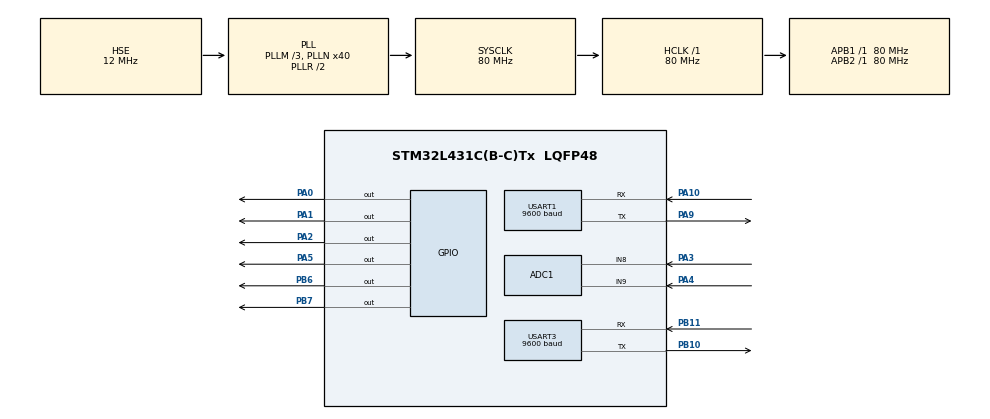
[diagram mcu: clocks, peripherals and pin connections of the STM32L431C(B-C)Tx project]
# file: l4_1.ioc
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ADC1.Channel-0\#ChannelRegularConversion=ADC_CHANNEL_8
ADC1.Channel-1\#ChannelRegularConversion=ADC_CHANNEL_9
ADC1.ContinuousConvMode=ENABLE
ADC1.DMAContinuousRequests=ENABLE
ADC1.NbrOfConversion=2
ADC1.NbrOfConversionFlag=1
ADC1.OffsetNumber-0\#ChannelRegularConversion=ADC_OFFSET_NONE
ADC1.OffsetNumber-1\#ChannelRegularConversion=ADC_OFFSET_NONE
ADC1.Rank-0\#ChannelRegularConversion=1
ADC1.Rank-1\#ChannelRegularConversion=2
ADC1.SamplingTime-0\#ChannelRegularConversion=ADC_SAMPLETIME_24CYCLES_5
ADC1.SamplingTime-1\#ChannelRegularConversion=ADC_SAMPLETIME_24CYCLES_5
ADC1.master=1
Dma.ADC1.2.Direction=DMA_PERIPH_TO_MEMORY
Dma.ADC1.2.Instance=DMA1_Channel1
Dma.ADC1.2.MemDataAlignment=DMA_MDATAALIGN_HALFWORD
Dma.ADC1.2.MemInc=DMA_MINC_ENABLE
Dma.ADC1.2.Mode=DMA_CIRCULAR
Dma.ADC1.2.PeriphDataAlignment=DMA_PDATAALIGN_HALFWORD
Dma.ADC1.2.PeriphInc=DMA_PINC_DISABLE
Dma.ADC1.2.Priority=DMA_PRIORITY_LOW
Dma.Request0=USART1_RX
Dma.Request1=USART3_RX
Dma.Request2=ADC1
Dma.Request3=USART1_TX
Dma.USART1_RX.0.Direction=DMA_PERIPH_TO_MEMORY
Dma.USART1_RX.0.Instance=DMA1_Channel5
Dma.USART1_RX.0.MemDataAlignment=DMA_MDATAALIGN_BYTE
Dma.USART1_RX.0.MemInc=DMA_MINC_ENABLE
Dma.USART1_RX.0.Mode=DMA_NORMAL
Dma.USART1_RX.0.PeriphDataAlignment=DMA_PDATAALIGN_BYTE
Dma.USART1_RX.0.PeriphInc=DMA_PINC_DISABLE
Dma.USART1_RX.0.Priority=DMA_PRIORITY_LOW
Dma.USART1_TX.3.Direction=DMA_MEMORY_TO_PERIPH
Dma.USART1_TX.3.Instance=DMA1_Channel4
Dma.USART1_TX.3.MemDataAlignment=DMA_MDATAALIGN_BYTE
Dma.USART1_TX.3.MemInc=DMA_MINC_ENABLE
Dma.USART1_TX.3.Mode=DMA_NORMAL
Dma.USART1_TX.3.PeriphDataAlignment=DMA_PDATAALIGN_BYTE
Dma.USART1_TX.3.PeriphInc=DMA_PINC_DISABLE
Dma.USART1_TX.3.Priority=DMA_PRIORITY_LOW
Dma.USART3_RX.1.Direction=DMA_PERIPH_TO_MEMORY
Dma.USART3_RX.1.Instance=DMA1_Channel3
Dma.USART3_RX.1.MemDataAlignment=DMA_MDATAALIGN_BYTE
Dma.USART3_RX.1.MemInc=DMA_MINC_ENABLE
Dma.USART3_RX.1.Mode=DMA_NORMAL
Dma.USART3_RX.1.PeriphDataAlignment=DMA_PDATAALIGN_BYTE
Dma.USART3_RX.1.PeriphInc=DMA_PINC_DISABLE
Dma.USART3_RX.1.Priority=DMA_PRIORITY_LOW
Mcu.Family=STM32L4
Mcu.Name=STM32L431C(B-C)Tx
Mcu.Package=LQFP48
NVIC.ADC1_IRQn=true\:0\:0\:false\:false\:true\:true\:true\:true
NVIC.DMA1_Channel1_IRQn=true\:0\:0\:false\:false\:true\:false\:true\:true
NVIC.DMA1_Channel3_IRQn=true\:0\:0\:false\:false\:true\:false\:true\:true
NVIC.DMA1_Channel4_IRQn=true\:0\:0\:false\:false\:true\:false\:true\:true
NVIC.DMA1_Channel5_IRQn=true\:0\:0\:false\:false\:true\:false\:true\:true
NVIC.PriorityGroup=NVIC_PRIORITYGROUP_4
NVIC.TIM2_IRQn=true\:0\:0\:false\:false\:true\:true\:true\:true
NVIC.USART1_IRQn=true\:0\:0\:false\:false\:true\:true\:true\:true
NVIC.USART3_IRQn=true\:0\:0\:false\:false\:true\:true\:true\:true
PA0.PinState=GPIO_PIN_SET
PA0.Signal=GPIO_Output
PA1.PinState=GPIO_PIN_SET
PA1.Signal=GPIO_Output
PA10.Mode=Asynchronous
PA10.Signal=USART1_RX
PA13\ (JTMS-SWDIO).Mode=Serial_Wire
PA13\ (JTMS-SWDIO).Signal=SYS_JTMS-SWDIO
PA14\ (JTCK-SWCLK).Mode=Serial_Wire
PA14\ (JTCK-SWCLK).Signal=SYS_JTCK-SWCLK
PA2.PinState=GPIO_PIN_SET
PA2.Signal=GPIO_Output
PA3.Signal=ADCx_IN8
PA4.Signal=ADCx_IN9
PA5.Signal=GPIO_Output
PA9.Mode=Asynchronous
PA9.Signal=USART1_TX
PB10.Mode=Asynchronous
PB10.Signal=USART3_TX
PB11.Mode=Asynchronous
PB11.Signal=USART3_RX
PB6.Signal=GPIO_Output
PB7.Signal=GPIO_Output
PH0-OSC_IN\ (PH0).Mode=HSE-External-Oscillator
PH0-OSC_IN\ (PH0).Signal=RCC_OSC_IN
PH1-OSC_OUT\ (PH1).Mode=HSE-External-Oscillator
PH1-OSC_OUT\ (PH1).Signal=RCC_OSC_OUT
ProjectManager.HeapSize=0x200
ProjectManager.StackSize=0x400
ProjectManager.TargetToolchain=MDK-ARM V5.32
RCC.ADCFreq_Value=32000000
RCC.AHBFreq_Value=80000000
RCC.APB1Freq_Value=80000000
RCC.APB1TimFreq_Value=80000000
RCC.APB2Freq_Value=80000000
RCC.APB2TimFreq_Value=80000000
RCC.CortexFreq_Value=80000000
RCC.HCLKFreq_Value=80000000
RCC.HSE_VALUE=12000000
RCC.HSI48_VALUE=48000000
RCC.HSI_VALUE=16000000
RCC.LSE_VALUE=32768
RCC.MSI_VALUE=4000000
RCC.PLLM=3
RCC.PLLN=40
RCC.PLLSAI1N=16
RCC.PLLSourceVirtual=RCC_PLLSOURCE_HSE
RCC.SYSCLKFreq_VALUE=80000000
RCC.SYSCLKSource=RCC_SYSCLKSOURCE_PLLCLK
RCC.VCOOutputFreq_Value=160000000
SH.ADCx_IN8.0=ADC1_IN8,IN8-Single-Ended
SH.ADCx_IN9.0=ADC1_IN9,IN9-Single-Ended
TIM2.Period=800 - 1
TIM2.Prescaler=79 - 1
TIM6.Prescaler=80 - 1
USART1.BaudRate=9600
USART1.Parity=PARITY_EVEN
USART1.VirtualMode-Asynchronous=VM_ASYNC
USART1.WordLength=WORDLENGTH_9B
USART3.BaudRate=9600
USART3.VirtualMode-Asynchronous=VM_ASYNC
USART3.WordLength=WORDLENGTH_8B
VP_TIM2_VS_ClockSourceINT.Mode=Internal
VP_TIM6_VS_ClockSourceINT.Mode=Enable_Timer
board=custom

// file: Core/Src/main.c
/* USER CODE BEGIN Header */
/**
  ******************************************************************************
  * @file           : main.c
  * @brief          : Main program body
  ******************************************************************************
  * @attention
  *
  * Copyright (c) 2026 STMicroelectronics.
  * All rights reserved.
  *
  * This software is licensed under terms that can be found in the LICENSE file
  * in the root directory of this software component.
  * If no LICENSE file comes with this software, it is provided AS-IS.
  *
  ******************************************************************************
  */
/* USER CODE END Header */
#include "main.h"
#include "adc.h"
#include "dma.h"
#include "tim.h"
#include "usart.h"
#include "gpio.h"

/* USER CODE BEGIN Includes */
#include "bsp.h"

/* USER CODE END Includes */

void SystemClock_Config(void);

int main(void)
{

  /* MCU Configuration--------------------------------------------------------*/

  /* Reset of all peripherals, Initializes the Flash interface and the Systick. */
  HAL_Init();

  /* Configure the system clock */
  SystemClock_Config();

  /* Initialize all configured peripherals */
  MX_GPIO_Init();
  MX_DMA_Init();
  MX_TIM2_Init();
  MX_TIM6_Init();
  MX_USART1_UART_Init();
  MX_USART3_UART_Init();
  MX_ADC1_Init();

  /* Infinite loop */
  /* USER CODE BEGIN WHILE */
	system_user_init();

  while (1)
  {
		scheduler_run();
    /* USER CODE END WHILE */

  }
}

void SystemClock_Config(void)
{
  RCC_OscInitTypeDef RCC_OscInitStruct = {0};
  RCC_ClkInitTypeDef RCC_ClkInitStruct = {0};

  /** Configure the main internal regulator output voltage
  */
  if (HAL_PWREx_ControlVoltageScaling(PWR_REGULATOR_VOLTAGE_SCALE1) != HAL_OK)
  {
    Error_Handler();
  }

  /** Initializes the RCC Oscillators according to the specified parameters
  * in the RCC_OscInitTypeDef structure.
  */
  RCC_OscInitStruct.OscillatorType = RCC_OSCILLATORTYPE_HSE;
  RCC_OscInitStruct.HSEState = RCC_HSE_ON;
  RCC_OscInitStruct.PLL.PLLState = RCC_PLL_ON;
  RCC_OscInitStruct.PLL.PLLSource = RCC_PLLSOURCE_HSE;
  RCC_OscInitStruct.PLL.PLLM = 3;
  RCC_OscInitStruct.PLL.PLLN = 40;
  RCC_OscInitStruct.PLL.PLLP = RCC_PLLP_DIV7;
  RCC_OscInitStruct.PLL.PLLQ = RCC_PLLQ_DIV2;
  RCC_OscInitStruct.PLL.PLLR = RCC_PLLR_DIV2;
  if (HAL_RCC_OscConfig(&RCC_OscInitStruct) != HAL_OK)
  {
    Error_Handler();
  }

  /** Initializes the CPU, AHB and APB buses clocks
  */
  RCC_ClkInitStruct.ClockType = RCC_CLOCKTYPE_HCLK|RCC_CLOCKTYPE_SYSCLK
                              |RCC_CLOCKTYPE_PCLK1|RCC_CLOCKTYPE_PCLK2;
  RCC_ClkInitStruct.SYSCLKSource = RCC_SYSCLKSOURCE_PLLCLK;
  RCC_ClkInitStruct.AHBCLKDivider = RCC_SYSCLK_DIV1;
  RCC_ClkInitStruct.APB1CLKDivider = RCC_HCLK_DIV1;
  RCC_ClkInitStruct.APB2CLKDivider = RCC_HCLK_DIV1;

  if (HAL_RCC_ClockConfig(&RCC_ClkInitStruct, FLASH_LATENCY_4) != HAL_OK)
  {
    Error_Handler();
  }
}

void Error_Handler(void)
{
  __disable_irq();
  while (1)
  {
  }
}
